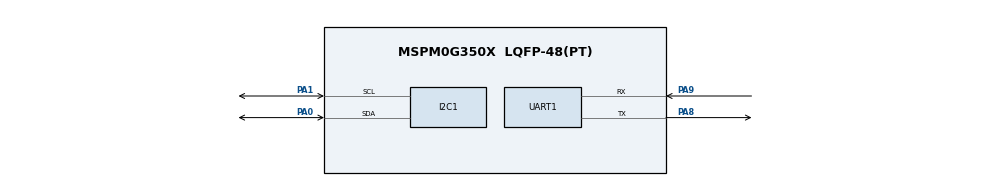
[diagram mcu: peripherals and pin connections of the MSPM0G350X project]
/**
 *
 * @cliArgs --device "MSPM0G350X" --part "Default" --package "LQFP-48(PT)" --product "mspm0_sdk@2.11.00.07"
 * @versions {"tool":"1.28.0+4712"}
 */

/**
 * Import the modules used in this configuration.
 */
const I2C    = scripting.addModule("/ti/driverlib/I2C", {}, false);
const I2C1   = I2C.addInstance();
const TIMER  = scripting.addModule("/ti/driverlib/TIMER", {}, false);
const TIMER1 = TIMER.addInstance();
const UART   = scripting.addModule("/ti/driverlib/UART", {}, false);
const UART1  = UART.addInstance();

/**
 * Write custom configuration values to the imported modules.
 */
I2C1.$name                             = "MPU6050_I2C";
I2C1.basicEnableController             = true;
I2C1.basicControllerStandardBusSpeed   = "Fast";
I2C1.intController                     = ["ARBITRATION_LOST","NACK","RXFIFO_TRIGGER","RX_DONE","TX_DONE"];
I2C1.peripheral.$assign                = "I2C0";
I2C1.peripheral.sdaPin.$assign         = "PA0";
I2C1.peripheral.sclPin.$assign         = "PA1";
I2C1.sdaPinConfig.$name                = "ti_driverlib_gpio_GPIOPinGeneric0";
I2C1.sdaPinConfig.hideOutputInversion  = scripting.forceWrite(false);
I2C1.sdaPinConfig.onlyInternalResistor = scripting.forceWrite(false);
I2C1.sdaPinConfig.passedPeripheralType = scripting.forceWrite("Digital");
I2C1.sclPinConfig.$name                = "ti_driverlib_gpio_GPIOPinGeneric1";
I2C1.sclPinConfig.hideOutputInversion  = scripting.forceWrite(false);
I2C1.sclPinConfig.onlyInternalResistor = scripting.forceWrite(false);
I2C1.sclPinConfig.passedPeripheralType = scripting.forceWrite("Digital");

const Board = scripting.addModule("/ti/driverlib/Board", {}, false);

const SYSCTL = scripting.addModule("/ti/driverlib/SYSCTL", {}, false);

TIMER1.$name              = "SAMPLE_TIMER";
TIMER1.timerMode          = "PERIODIC";
TIMER1.timerPeriod        = "10 ms";
TIMER1.timerClkPrescale   = 32;
TIMER1.interrupts         = ["ZERO"];
TIMER1.peripheral.$assign = "TIMG0";

UART1.$name                            = "HC05_UART";
UART1.targetBaudRate                   = 115200;
UART1.enabledInterrupts                = ["RX"];
UART1.peripheral.$assign               = "UART1";
UART1.peripheral.rxPin.$assign         = "PA9";
UART1.peripheral.txPin.$assign         = "PA8";
UART1.txPinConfig.$name                = "ti_driverlib_gpio_GPIOPinGeneric2";
UART1.txPinConfig.direction            = scripting.forceWrite("OUTPUT");
UART1.txPinConfig.hideOutputInversion  = scripting.forceWrite(false);
UART1.txPinConfig.onlyInternalResistor = scripting.forceWrite(false);
UART1.txPinConfig.passedPeripheralType = scripting.forceWrite("Digital");
UART1.rxPinConfig.$name                = "ti_driverlib_gpio_GPIOPinGeneric3";
UART1.rxPinConfig.hideOutputInversion  = scripting.forceWrite(false);
UART1.rxPinConfig.onlyInternalResistor = scripting.forceWrite(false);
UART1.rxPinConfig.passedPeripheralType = scripting.forceWrite("Digital");

/**
 * Pinmux solution for unlocked pins/peripherals. This ensures that minor changes to the automatic solver in a future
 * version of the tool will not impact the pinmux you originally saw.  These lines can be completely deleted in order to
 * re-solve from scratch.
 */
Board.peripheral.$suggestSolution          = "DEBUGSS";
Board.peripheral.swclkPin.$suggestSolution = "PA20";
Board.peripheral.swdioPin.$suggestSolution = "PA19";
SYSCTL.peripheral.$suggestSolution         = "SYSCTL";
